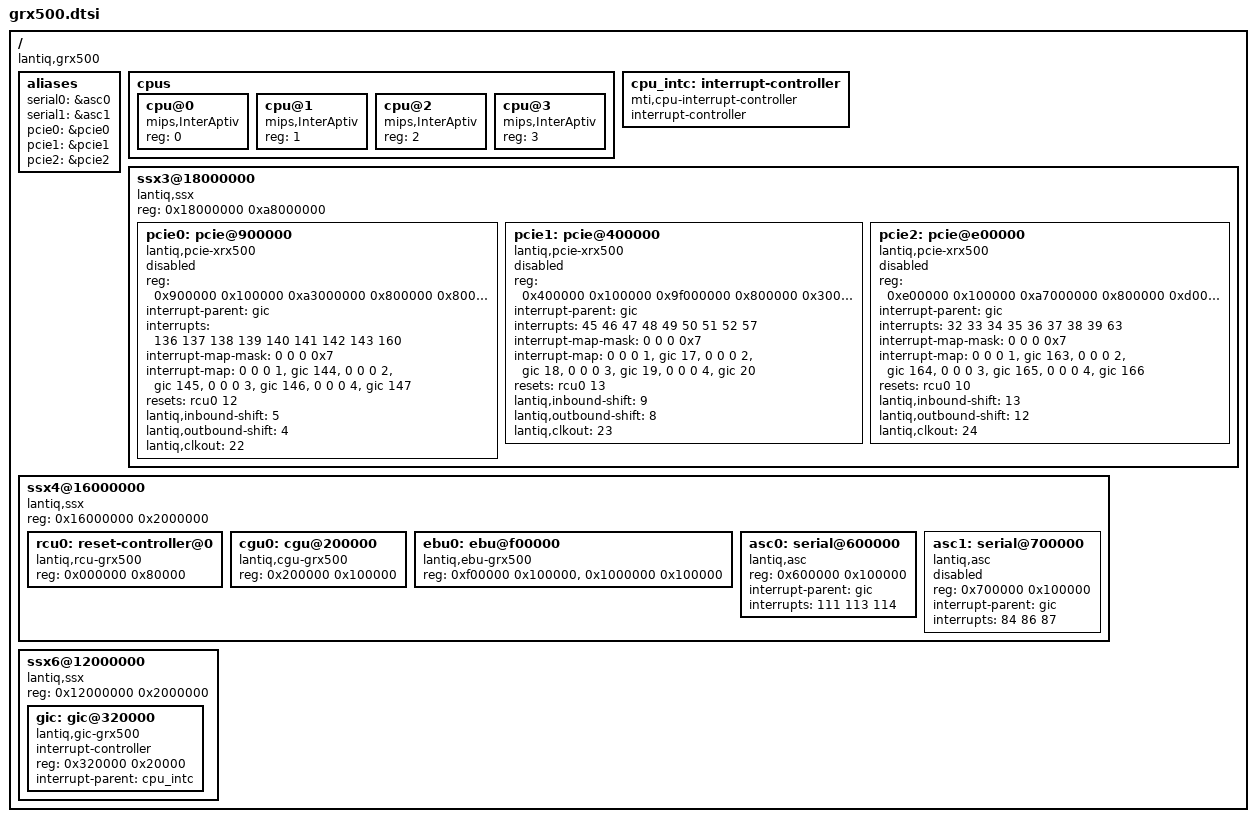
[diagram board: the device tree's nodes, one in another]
// SPDX-License-Identifier: GPL-2.0-only
/ {
	#address-cells = <1>;
	#size-cells = <1>;
	compatible = "lantiq,grx500", "lantiq,xrx500";

	aliases {
		serial0 = &asc0;
		serial1 = &asc1;
		pcie0   = &pcie0;
		pcie1   = &pcie1;
		pcie2   = &pcie2;
	};

	cpus {
		#address-cells = <1>;
		#size-cells = <0>;

		cpu@0 {
			device_type = "cpu";
			compatible = "mips,InterAptiv";
			reg = <0>;
		};
		cpu@1 {
			device_type = "cpu";
			compatible = "mips,InterAptiv";
			reg = <1>;
		};
		cpu@2 {
			device_type = "cpu";
			compatible = "mips,InterAptiv";
			reg = <2>;
		};
		cpu@3 {
			device_type = "cpu";
			compatible = "mips,InterAptiv";
			reg = <3>;
		};
	};

	cpu_intc: interrupt-controller {
		compatible = "mti,cpu-interrupt-controller";
		interrupt-controller;
		#interrupt-cells = <1>;
	};

	ssx3@18000000 {
		#address-cells = <1>;
		#size-cells = <1>;
		compatible = "lantiq,ssx", "simple-bus";
		reg = <0x18000000 0xa8000000>;
		ranges = <0x0 0x18000000 0xa8000000>;

		pcie0: pcie@900000 {
			status = "disabled";
			compatible = "lantiq,pcie-xrx500";
			device_type = "pci";
			#address-cells = <3>;
			#size-cells = <2>;
			reg = <
				0x900000 0x100000
				0xa3000000 0x800000
				0x800000 0x100000
				0x500000 0x100000
				0x600000 0x100000
				0x700000 0x100000
			>;
			reg-names = "csr", "cfg", "app", "phy", "msi", "pic";
			interrupt-parent = <&gic>;
			interrupts = <136 137 138 139 140 141 142 143 160>;
			interrupt-names = "msi0", "msi1", "msi2", "msi3", "msi4", "msi5", "msi6", "msi7", "ir";
			#interrupt-cells = <1>;
			interrupt-map-mask = <0 0 0 0x7>;
			interrupt-map = <0 0 0 1 &gic 144>,
					<0 0 0 2 &gic 145>,
					<0 0 0 3 &gic 146>,
					<0 0 0 4 &gic 147>;
			ranges = <0x02000000 0 0xa0000000 0xa0000000 0 0x03000000
				  0x01000000 0 0xa3800000 0xa3800000 0 0x00100000>;
			resets = <&rcu0 12>;
			reset-names = "phy";
			lantiq,inbound-shift = <5>;
			lantiq,outbound-shift = <4>;
			lantiq,clkout = <22>;
		};

		pcie1: pcie@400000 {
			status = "disabled";
			compatible = "lantiq,pcie-xrx500";
			device_type = "pci";
			#address-cells = <3>;
			#size-cells = <2>;
			reg = <
				0x400000 0x100000
				0x9f000000 0x800000
				0x300000 0x100000
				0x000000 0x100000
				0x100000 0x100000
				0x200000 0x100000
			>;
			reg-names = "csr", "cfg", "app", "phy", "msi", "pic";
			interrupt-parent = <&gic>;
			interrupts = <45 46 47 48 49 50 51 52 57>;
			interrupt-names = "msi0", "msi1", "msi2", "msi3", "msi4", "msi5", "msi6", "msi7", "ir";
			#interrupt-cells = <1>;
			interrupt-map-mask = <0 0 0 0x7>;
			interrupt-map = <0 0 0 1 &gic 17>,
					<0 0 0 2 &gic 18>,
					<0 0 0 3 &gic 19>,
					<0 0 0 4 &gic 20>;
			ranges = <0x02000000 0 0x9c000000 0x9c000000 0 0x03000000
				  0x01000000 0 0x9f800000 0x9f800000 0 0x00100000>;
			resets = <&rcu0 13>;
			reset-names = "phy";
			lantiq,inbound-shift = <9>;
			lantiq,outbound-shift = <8>;
			lantiq,clkout = <23>;
		};

		pcie2: pcie@e00000 {
			status = "disabled";
			compatible = "lantiq,pcie-xrx500";
			#address-cells = <3>;
			#size-cells = <2>;
			device_type = "pci";
			reg = <
				0xe00000 0x100000
				0xa7000000 0x800000
				0xd00000 0x100000
				0xa00000 0x100000
				0xb00000 0x100000
				0xc00000 0x100000
			>;
			reg-names = "csr", "cfg", "app", "phy", "msi", "pic";
			interrupt-parent = <&gic>;
			interrupts = <32 33 34 35 36 37 38 39 63>;
			interrupt-names = "msi0", "msi1", "msi2", "msi3", "msi4", "msi5", "msi6", "msi7", "ir";
			#interrupt-cells = <1>;
			interrupt-map-mask = <0 0 0 0x7>;
			interrupt-map = <0 0 0 1 &gic 163>,
					<0 0 0 2 &gic 164>,
					<0 0 0 3 &gic 165>,
					<0 0 0 4 &gic 166>;
			ranges = <0x02000000 0 0xa4000000 0xa4000000 0 0x03000000
				  0x01000000 0 0xa7800000 0xa7800000 0 0x00100000>;
			resets = <&rcu0 10>;
			reset-names = "phy";
			lantiq,inbound-shift = <13>;
			lantiq,outbound-shift = <12>;
			lantiq,clkout = <24>;
		};
	};

	ssx4@16000000 {
		#address-cells = <1>;
		#size-cells = <1>;
		compatible = "lantiq,ssx", "simple-bus";
		reg = <0x16000000 0x2000000>;
		ranges = <0x0 0x16000000 0x02000000>;

		rcu0: reset-controller@0 {
			compatible = "lantiq,rcu-grx500", "lantiq,rcu-xrx500";
			reg = <0x000000 0x80000>;
			#reset-cells = <1>;
		};

		cgu0: cgu@200000 {
			compatible = "lantiq,cgu-grx500", "lantiq,cgu-xrx500";
			reg = <0x200000 0x100000>;
		};

		ebu0: ebu@f00000 {
			compatible = "lantiq,ebu-grx500", "lantiq,ebu-xrx500";
			reg = <0xf00000 0x100000>,
			      <0x1000000 0x100000>;
			reg-names = "ebunand_reg", "hsnand_reg";
		};

		asc0: serial@600000 {
			compatible = "lantiq,asc";
			reg = <0x600000 0x100000>;
			interrupt-parent = <&gic>;
			interrupts = <111 113 114>;
		};

		asc1: serial@700000 {
			compatible = "lantiq,asc";
			reg = <0x700000 0x100000>;
			interrupt-parent = <&gic>;
			interrupts = <84 86 87>;
			status = "disabled";
		};
	};

	ssx6@12000000 {
		#address-cells = <1>;
		#size-cells = <1>;
		compatible = "lantiq,ssx", "simple-bus";
		reg = <0x12000000 0x2000000>;
		ranges = <0x0 0x12000000 0x02000000>;

		gic: gic@320000 {
			#interrupt-cells = <1>;
			interrupt-controller;
			compatible = "lantiq,gic-grx500", "mti,gic";
			reg = <0x320000 0x20000>;
			interrupt-parent = <&cpu_intc>;
		};
	};
};
